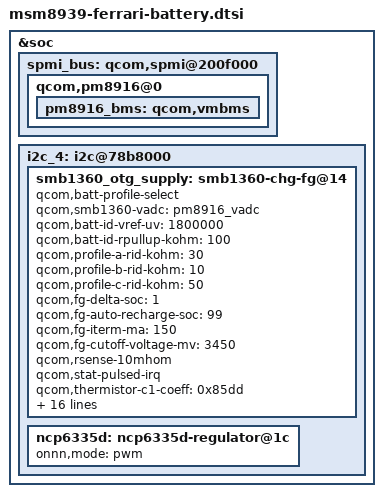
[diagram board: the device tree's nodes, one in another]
/* Copyright (c) 2014-2015, The Linux Foundation. All rights reserved.
 *
 * This program is free software; you can redistribute it and/or modify
 * it under the terms of the GNU General Public License version 2 and
 * only version 2 as published by the Free Software Foundation.
 *
 * This program is distributed in the hope that it will be useful,
 * but WITHOUT ANY WARRANTY; without even the implied warranty of
 * MERCHANTABILITY or FITNESS FOR A PARTICULAR PURPOSE.  See the
 * GNU General Public License for more details.
 */

&soc {
	spmi_bus: qcom,spmi@200f000 {
		qcom,pm8916@0 {
			pm8916_bms: qcom,vmbms {
				/delete-property/ qcom,disable-bms;
			};
		};
	};

	i2c_4: i2c@78b8000 { /* BLSP1 QUP4 */
		smb1360_otg_supply: smb1360-chg-fg@14 {
			qcom,batt-profile-select;
			qcom,smb1360-vadc = <&pm8916_vadc>;
			qcom,batt-id-vref-uv = <1800000>;
			qcom,batt-id-rpullup-kohm = <100>;
			qcom,profile-a-rid-kohm = <30>;
			qcom,profile-b-rid-kohm = <10>;
			qcom,profile-c-rid-kohm = <50>;
			qcom,fg-delta-soc = <1>;
			qcom,fg-auto-recharge-soc = <99>;
			qcom,fg-iterm-ma = <150>;
			qcom,fg-cutoff-voltage-mv = <3450>;
			qcom,rsense-10mhom;

			qcom,stat-pulsed-irq;
			qcom,thermistor-c1-coeff = <0x85dd>;
			qcom,float-voltage-mv = <4400>;
			qcom,iterm-ma = <150>;
			qcom,shdn-after-pwroff;
			qcom,thermal-mitigation = <1500 1200 900 700>;
			qcom,hot-bat-decidegc = <600>;
			qcom,cold-bat-decidegc = <0>;
			qcom,soft-jeita-supported;
			qcom,warm-bat-decidegc = <450>;
			qcom,cool-bat-decidegc = <0>;
			qcom,warm-bat-mv = <4100>;
			qcom,cool-bat-mv = <4100>;
			qcom,warm-bat-ma = <200>;
			qcom,cool-bat-ma = <200>;

			qcom,otg-batt-curr-limit = <1500>;
			qcom,fg-reset-at-pon;
			qcom,otp-rslow-cfg;

			/delete-property/ qcom,charging-disabled;
		};

		ncp6335d: ncp6335d-regulator@1c {
			onnn,mode = "pwm";
		};
	};
};
